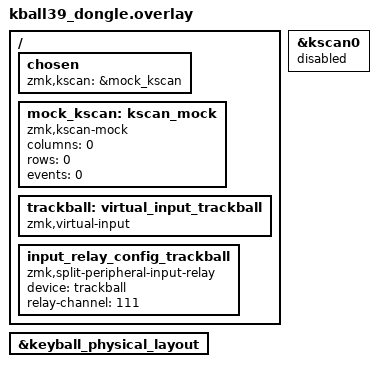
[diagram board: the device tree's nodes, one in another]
/* Dongle mode: USB receiver is the central and has no key matrix. */

#include "../keyball_nano/keyball39.dtsi"

&kscan0 {
    status = "disabled";
};

&keyball_physical_layout {
    /delete-property/ kscan;
};

/ {
    chosen {
        zmk,kscan = &mock_kscan;
    };

    mock_kscan: kscan_mock {
        compatible = "zmk,kscan-mock";
        columns = <0>;
        rows = <0>;
        events = <0>;
    };

    trackball: virtual_input_trackball {
        compatible = "zmk,virtual-input";
    };

    input_relay_config_trackball {
        compatible = "zmk,split-peripheral-input-relay";
        device = <&trackball>;
        relay-channel = <111>;
    };
};
